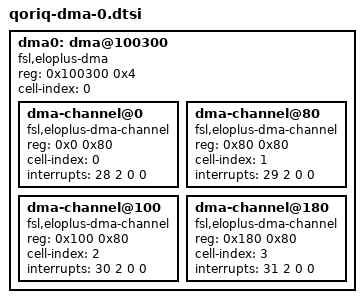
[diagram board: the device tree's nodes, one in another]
dma0: dma@100300 {
	#address-cells = <1>;
	#size-cells = <1>;
	compatible = "fsl,eloplus-dma";
	reg = <0x100300 0x4>;
	ranges = <0x0 0x100100 0x200>;
	cell-index = <0>;
	dma-channel@0 {
		compatible = "fsl,eloplus-dma-channel";
		reg = <0x0 0x80>;
		cell-index = <0>;
		interrupts = <28 2 0 0>;
	};
	dma-channel@80 {
		compatible = "fsl,eloplus-dma-channel";
		reg = <0x80 0x80>;
		cell-index = <1>;
		interrupts = <29 2 0 0>;
	};
	dma-channel@100 {
		compatible = "fsl,eloplus-dma-channel";
		reg = <0x100 0x80>;
		cell-index = <2>;
		interrupts = <30 2 0 0>;
	};
	dma-channel@180 {
		compatible = "fsl,eloplus-dma-channel";
		reg = <0x180 0x80>;
		cell-index = <3>;
		interrupts = <31 2 0 0>;
	};
};
